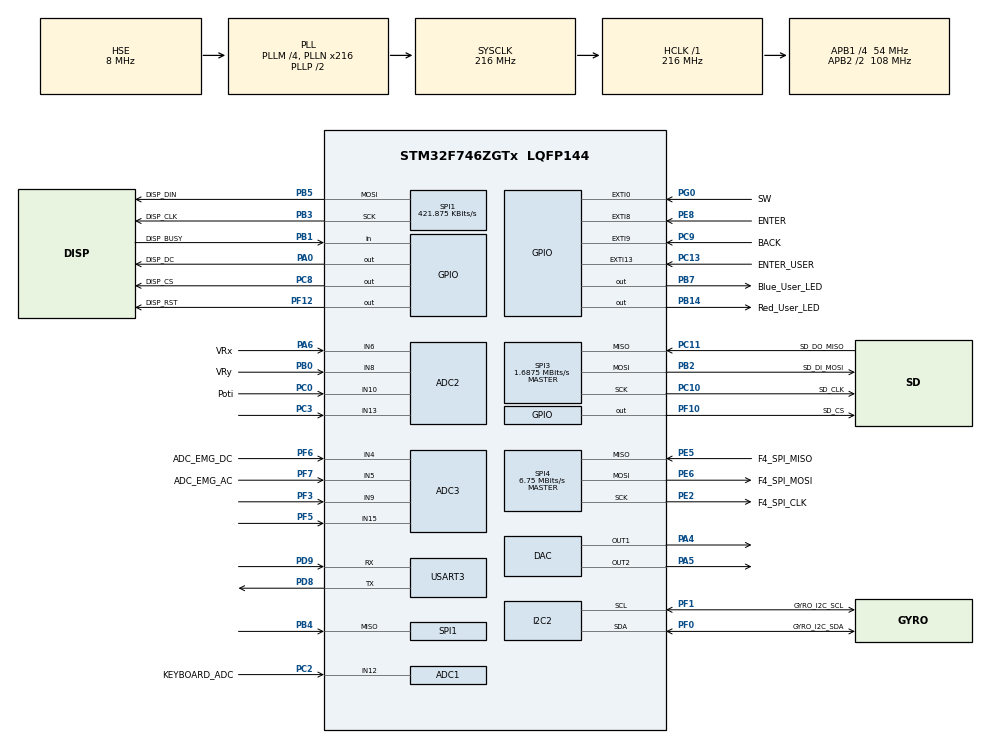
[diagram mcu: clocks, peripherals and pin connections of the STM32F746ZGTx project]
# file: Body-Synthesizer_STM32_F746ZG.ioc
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ADC1.Channel-0\#ChannelRegularConversion=ADC_CHANNEL_12
ADC1.ClockPrescaler=ADC_CLOCK_SYNC_PCLK_DIV8
ADC1.DMAContinuousRequests=ENABLE
ADC1.EOCSelection=ADC_EOC_SEQ_CONV
ADC1.ExternalTrigConv=ADC_EXTERNALTRIGCONV_T5_TRGO
ADC1.NbrOfConversion=1
ADC1.NbrOfConversionFlag=1
ADC1.Rank-0\#ChannelRegularConversion=1
ADC1.SamplingTime-0\#ChannelRegularConversion=ADC_SAMPLETIME_15CYCLES
ADC1.ScanConvMode=ADC_SCAN_ENABLE
ADC1.master=1
ADC2.Channel-0\#ChannelRegularConversion=ADC_CHANNEL_6
ADC2.Channel-1\#ChannelRegularConversion=ADC_CHANNEL_8
ADC2.Channel-2\#ChannelRegularConversion=ADC_CHANNEL_10
ADC2.Channel-3\#ChannelRegularConversion=ADC_CHANNEL_13
ADC2.ClockPrescaler=ADC_CLOCK_SYNC_PCLK_DIV8
ADC2.DMAContinuousRequests=ENABLE
ADC2.ExternalTrigConv=ADC_EXTERNALTRIGCONV_T6_TRGO
ADC2.NbrOfConversion=4
ADC2.NbrOfConversionFlag=1
ADC2.Rank-0\#ChannelRegularConversion=1
ADC2.Rank-1\#ChannelRegularConversion=2
ADC2.Rank-2\#ChannelRegularConversion=3
ADC2.Rank-3\#ChannelRegularConversion=4
ADC2.SamplingTime-0\#ChannelRegularConversion=ADC_SAMPLETIME_15CYCLES
ADC2.SamplingTime-1\#ChannelRegularConversion=ADC_SAMPLETIME_15CYCLES
ADC2.SamplingTime-2\#ChannelRegularConversion=ADC_SAMPLETIME_15CYCLES
ADC2.SamplingTime-3\#ChannelRegularConversion=ADC_SAMPLETIME_15CYCLES
ADC2.ScanConvMode=ADC_SCAN_ENABLE
ADC3.Channel-0\#ChannelRegularConversion=ADC_CHANNEL_4
ADC3.Channel-2\#ChannelRegularConversion=ADC_CHANNEL_5
ADC3.ClockPrescaler=ADC_CLOCK_SYNC_PCLK_DIV8
ADC3.DMAContinuousRequests=ENABLE
ADC3.EOCSelection=ADC_EOC_SEQ_CONV
ADC3.ExternalTrigConv=ADC_EXTERNALTRIGCONV_T1_TRGO
ADC3.NbrOfConversion=2
ADC3.NbrOfConversionFlag=1
ADC3.Rank-0\#ChannelRegularConversion=1
ADC3.Rank-2\#ChannelRegularConversion=2
ADC3.SamplingTime-0\#ChannelRegularConversion=ADC_SAMPLETIME_15CYCLES
ADC3.SamplingTime-2\#ChannelRegularConversion=ADC_SAMPLETIME_15CYCLES
ADC3.ScanConvMode=ADC_SCAN_ENABLE
DAC.DAC_Trigger=DAC_TRIGGER_T8_TRGO
DAC.DAC_Trigger2=DAC_TRIGGER_T8_TRGO
Dma.ADC1.2.Direction=DMA_PERIPH_TO_MEMORY
Dma.ADC1.2.FIFOMode=DMA_FIFOMODE_DISABLE
Dma.ADC1.2.Instance=DMA2_Stream0
Dma.ADC1.2.MemDataAlignment=DMA_MDATAALIGN_WORD
Dma.ADC1.2.MemInc=DMA_MINC_ENABLE
Dma.ADC1.2.Mode=DMA_NORMAL
Dma.ADC1.2.PeriphDataAlignment=DMA_PDATAALIGN_WORD
Dma.ADC1.2.PeriphInc=DMA_PINC_DISABLE
Dma.ADC1.2.Priority=DMA_PRIORITY_VERY_HIGH
Dma.ADC2.1.Direction=DMA_PERIPH_TO_MEMORY
Dma.ADC2.1.FIFOMode=DMA_FIFOMODE_DISABLE
Dma.ADC2.1.Instance=DMA2_Stream2
Dma.ADC2.1.MemDataAlignment=DMA_MDATAALIGN_HALFWORD
Dma.ADC2.1.MemInc=DMA_MINC_ENABLE
Dma.ADC2.1.Mode=DMA_CIRCULAR
Dma.ADC2.1.PeriphDataAlignment=DMA_PDATAALIGN_HALFWORD
Dma.ADC2.1.PeriphInc=DMA_PINC_DISABLE
Dma.ADC2.1.Priority=DMA_PRIORITY_HIGH
Dma.ADC3.3.Direction=DMA_PERIPH_TO_MEMORY
Dma.ADC3.3.FIFOMode=DMA_FIFOMODE_DISABLE
Dma.ADC3.3.Instance=DMA2_Stream1
Dma.ADC3.3.MemDataAlignment=DMA_MDATAALIGN_WORD
Dma.ADC3.3.MemInc=DMA_MINC_ENABLE
Dma.ADC3.3.Mode=DMA_CIRCULAR
Dma.ADC3.3.PeriphDataAlignment=DMA_PDATAALIGN_WORD
Dma.ADC3.3.PeriphInc=DMA_PINC_DISABLE
Dma.ADC3.3.Priority=DMA_PRIORITY_HIGH
Dma.DAC1.0.Direction=DMA_MEMORY_TO_PERIPH
Dma.DAC1.0.FIFOMode=DMA_FIFOMODE_DISABLE
Dma.DAC1.0.Instance=DMA1_Stream5
Dma.DAC1.0.MemDataAlignment=DMA_MDATAALIGN_WORD
Dma.DAC1.0.MemInc=DMA_MINC_ENABLE
Dma.DAC1.0.Mode=DMA_CIRCULAR
Dma.DAC1.0.PeriphDataAlignment=DMA_PDATAALIGN_WORD
Dma.DAC1.0.PeriphInc=DMA_PINC_DISABLE
Dma.DAC1.0.Priority=DMA_PRIORITY_VERY_HIGH
Dma.DAC2.4.Direction=DMA_MEMORY_TO_PERIPH
Dma.DAC2.4.FIFOMode=DMA_FIFOMODE_DISABLE
Dma.DAC2.4.Instance=DMA1_Stream6
Dma.DAC2.4.MemDataAlignment=DMA_MDATAALIGN_WORD
Dma.DAC2.4.MemInc=DMA_MINC_ENABLE
Dma.DAC2.4.Mode=DMA_CIRCULAR
Dma.DAC2.4.PeriphDataAlignment=DMA_PDATAALIGN_WORD
Dma.DAC2.4.PeriphInc=DMA_PINC_DISABLE
Dma.DAC2.4.Priority=DMA_PRIORITY_VERY_HIGH
Dma.Request0=DAC1
Dma.Request1=ADC2
Dma.Request2=ADC1
Dma.Request3=ADC3
Dma.Request4=DAC2
Dma.Request5=SPI4_RX
Dma.Request6=SPI4_TX
Dma.SPI4_RX.5.Direction=DMA_PERIPH_TO_MEMORY
Dma.SPI4_RX.5.FIFOMode=DMA_FIFOMODE_DISABLE
Dma.SPI4_RX.5.Instance=DMA2_Stream3
Dma.SPI4_RX.5.MemDataAlignment=DMA_MDATAALIGN_BYTE
Dma.SPI4_RX.5.MemInc=DMA_MINC_ENABLE
Dma.SPI4_RX.5.Mode=DMA_NORMAL
Dma.SPI4_RX.5.PeriphDataAlignment=DMA_PDATAALIGN_BYTE
Dma.SPI4_RX.5.PeriphInc=DMA_PINC_DISABLE
Dma.SPI4_RX.5.Priority=DMA_PRIORITY_LOW
Dma.SPI4_TX.6.Direction=DMA_MEMORY_TO_PERIPH
Dma.SPI4_TX.6.FIFOMode=DMA_FIFOMODE_DISABLE
Dma.SPI4_TX.6.Instance=DMA2_Stream4
Dma.SPI4_TX.6.MemDataAlignment=DMA_MDATAALIGN_BYTE
Dma.SPI4_TX.6.MemInc=DMA_MINC_ENABLE
Dma.SPI4_TX.6.Mode=DMA_NORMAL
Dma.SPI4_TX.6.PeriphDataAlignment=DMA_PDATAALIGN_BYTE
Dma.SPI4_TX.6.PeriphInc=DMA_PINC_DISABLE
Dma.SPI4_TX.6.Priority=DMA_PRIORITY_LOW
FATFS._MAX_SS=4096
FATFS._USE_LFN=1
I2C2.Timing=0x20404768
Mcu.Family=STM32F7
Mcu.Name=STM32F746ZGTx
Mcu.Package=LQFP144
NVIC.ADC_IRQn=true\:0\:0\:false\:false\:true\:true\:true
NVIC.DMA1_Stream5_IRQn=true\:0\:0\:false\:false\:true\:false\:true
NVIC.DMA1_Stream6_IRQn=true\:0\:0\:false\:false\:true\:false\:true
NVIC.DMA2_Stream0_IRQn=true\:1\:0\:true\:false\:true\:false\:true
NVIC.DMA2_Stream1_IRQn=true\:1\:0\:true\:false\:true\:false\:true
NVIC.DMA2_Stream2_IRQn=true\:2\:0\:true\:false\:true\:false\:true
NVIC.DMA2_Stream3_IRQn=true\:1\:0\:true\:false\:true\:false\:true
NVIC.DMA2_Stream4_IRQn=true\:1\:0\:true\:false\:true\:false\:true
NVIC.EXTI15_10_IRQn=true\:1\:0\:true\:false\:true\:true\:true
NVIC.EXTI9_5_IRQn=true\:0\:0\:true\:false\:true\:true\:true
NVIC.PriorityGroup=NVIC_PRIORITYGROUP_4
NVIC.SPI4_IRQn=true\:1\:0\:true\:false\:true\:true\:true
NVIC.TIM1_BRK_TIM9_IRQn=true\:1\:0\:true\:false\:true\:true\:true
NVIC.TIM2_IRQn=true\:1\:0\:true\:false\:true\:true\:true
NVIC.TIM3_IRQn=true\:0\:0\:true\:false\:true\:true\:true
NVIC.TIM4_IRQn=true\:1\:0\:true\:false\:true\:true\:true
NVIC.TIM5_IRQn=true\:1\:0\:true\:false\:true\:true\:true
NVIC.TIM7_IRQn=true\:1\:0\:true\:false\:true\:true\:true
NVIC.TIM8_TRG_COM_TIM14_IRQn=true\:1\:0\:true\:false\:true\:true\:true
PA0/WKUP.GPIO_Label=DISP_DC
PA0/WKUP.Signal=GPIO_Output
PA2.Signal=USART2_TX
PA4.Signal=COMP_DAC1_group
PA5.Signal=COMP_DAC2_group
PA6.GPIO_Label=VRx
PA6.Signal=ADCx_IN6
PB0.GPIO_Label=VRy
PB0.Signal=ADCx_IN8
PB1.GPIO_Label=DISP_BUSY
PB1.Signal=GPIO_Input
PB14.GPIO_Label=Red_User_LED
PB14.Signal=GPIO_Output
PB2.GPIO_Label=SD_DI_MOSI
PB2.Mode=Full_Duplex_Master
PB2.Signal=SPI3_MOSI
PB3.GPIO_Label=DISP_CLK
PB3.Mode=Full_Duplex_Master
PB3.Signal=SPI1_SCK
PB4.Mode=Full_Duplex_Master
PB4.Signal=SPI1_MISO
PB5.GPIO_Label=DISP_DIN
PB5.Mode=Full_Duplex_Master
PB5.Signal=SPI1_MOSI
PB7.GPIO_Label=Blue_User_LED
PB7.Signal=GPIO_Output
PC0.GPIO_Label=Poti
PC0.Signal=ADCx_IN10
PC10.GPIO_Label=SD_CLK
PC10.Mode=Full_Duplex_Master
PC10.Signal=SPI3_SCK
PC11.GPIO_Label=SD_DO_MISO
PC11.Mode=Full_Duplex_Master
PC11.Signal=SPI3_MISO
PC13.GPIO_Label=ENTER_USER
PC13.Signal=GPXTI13
PC2.GPIO_Label=KEYBOARD_ADC
PC2.Signal=ADCx_IN12
PC3.Signal=ADCx_IN13
PC8.GPIO_Label=DISP_CS
PC8.GPIO_ModeDefaultOutputPP=GPIO_MODE_OUTPUT_PP
PC8.Signal=GPIO_Output
PC9.GPIO_Label=BACK
PC9.Signal=GPXTI9
PD6.Signal=USART2_RX
PD8.Mode=Asynchronous
PD8.Signal=USART3_TX
PD9.Mode=Asynchronous
PD9.Signal=USART3_RX
PE2.GPIO_Label=F4_SPI_CLK
PE2.Mode=Full_Duplex_Master
PE2.Signal=SPI4_SCK
PE5.GPIO_Label=F4_SPI_MISO
PE5.Mode=Full_Duplex_Master
PE5.Signal=SPI4_MISO
PE6.GPIO_Label=F4_SPI_MOSI
PE6.Mode=Full_Duplex_Master
PE6.Signal=SPI4_MOSI
PE8.GPIO_Label=ENTER
PE8.Signal=GPXTI8
PF0.GPIO_Label=GYRO_I2C_SDA
PF0.Mode=I2C
PF0.Signal=I2C2_SDA
PF1.GPIO_Label=GYRO_I2C_SCL
PF1.Mode=I2C
PF1.Signal=I2C2_SCL
PF10.GPIO_Label=SD_CS
PF10.Signal=GPIO_Output
PF12.GPIO_Label=DISP_RST
PF12.Signal=GPIO_Output
PF3.Mode=IN9
PF3.Signal=ADC3_IN9
PF5.Mode=IN15
PF5.Signal=ADC3_IN15
PF6.GPIO_Label=ADC_EMG_DC
PF6.Mode=IN4
PF6.Signal=ADC3_IN4
PF7.GPIO_Label=ADC_EMG_AC
PF7.Mode=IN5
PF7.Signal=ADC3_IN5
PG0.GPIO_Label=SW
PG0.GPIO_ModeDefaultEXTI=GPIO_MODE_IT_FALLING
PG0.Signal=GPXTI0
PH0/OSC_IN.Mode=HSE-External-Oscillator
PH0/OSC_IN.Signal=RCC_OSC_IN
PH1/OSC_OUT.Mode=HSE-External-Oscillator
PH1/OSC_OUT.Signal=RCC_OSC_OUT
ProjectManager.HeapSize=0x200
ProjectManager.StackSize=0x400
ProjectManager.TargetToolchain=STM32CubeIDE
RCC.AHBFreq_Value=216000000
RCC.APB1CLKDivider=RCC_HCLK_DIV4
RCC.APB1Freq_Value=54000000
RCC.APB1TimFreq_Value=108000000
RCC.APB2CLKDivider=RCC_HCLK_DIV2
RCC.APB2Freq_Value=108000000
RCC.APB2TimFreq_Value=216000000
RCC.CortexFreq_Value=216000000
RCC.HCLKFreq_Value=216000000
RCC.HSE_VALUE=8000000
RCC.HSI_VALUE=16000000
RCC.LSE_VALUE=32768
RCC.PLLM=4
RCC.PLLN=216
RCC.PLLSourceVirtual=RCC_PLLSOURCE_HSE
RCC.SYSCLKFreq_VALUE=216000000
RCC.SYSCLKSource=RCC_SYSCLKSOURCE_PLLCLK
RCC.USBFreq_Value=216000000
RCC.VCOOutputFreq_Value=432000000
SH.ADCx_IN10.0=ADC2_IN10,IN10
SH.ADCx_IN12.0=ADC1_IN12,IN12
SH.ADCx_IN13.0=ADC2_IN13,IN13
SH.ADCx_IN6.0=ADC2_IN6,IN6
SH.ADCx_IN8.0=ADC2_IN8,IN8
SH.COMP_DAC1_group.0=DAC_OUT1,DAC_OUT1
SH.COMP_DAC2_group.0=DAC_OUT2,DAC_OUT2
SPI1.BaudRatePrescaler=SPI_BAUDRATEPRESCALER_256
SPI1.CalculateBaudRate=421.875 KBits/s
SPI1.DataSize=SPI_DATASIZE_8BIT
SPI1.Direction=SPI_DIRECTION_2LINES
SPI1.Mode=SPI_MODE_MASTER
SPI1.VirtualType=VM_MASTER
SPI3.BaudRatePrescaler=SPI_BAUDRATEPRESCALER_32
SPI3.CalculateBaudRate=1.6875 MBits/s
SPI3.DataSize=SPI_DATASIZE_8BIT
SPI3.Direction=SPI_DIRECTION_2LINES
SPI3.Mode=SPI_MODE_MASTER
SPI3.VirtualType=VM_MASTER
SPI4.BaudRatePrescaler=SPI_BAUDRATEPRESCALER_16
SPI4.CLKPolarity=SPI_POLARITY_HIGH
SPI4.CalculateBaudRate=6.75 MBits/s
SPI4.DataSize=SPI_DATASIZE_8BIT
SPI4.Direction=SPI_DIRECTION_2LINES
SPI4.Mode=SPI_MODE_MASTER
SPI4.NSSPMode=SPI_NSS_PULSE_DISABLE
SPI4.VirtualType=VM_MASTER
TIM1.AutoReloadPreload=TIM_AUTORELOAD_PRELOAD_ENABLE
TIM1.Period=10000
TIM1.Prescaler=215
TIM1.TIM_MasterOutputTrigger=TIM_TRGO_UPDATE
TIM2.Period=59999
TIM2.Prescaler=4
TIM3.AutoReloadPreload=TIM_AUTORELOAD_PRELOAD_ENABLE
TIM3.TIM_MasterOutputTrigger=TIM_TRGO_UPDATE
TIM4.Period=59999
TIM4.Prescaler=4
TIM5.AutoReloadPreload=TIM_AUTORELOAD_PRELOAD_ENABLE
TIM5.Period=53999
TIM5.TIM_MasterOutputTrigger=TIM_TRGO_UPDATE
TIM6.AutoReloadPreload=TIM_AUTORELOAD_PRELOAD_ENABLE
TIM6.Period=53999
TIM6.TIM_MasterOutputTrigger=TIM_TRGO_UPDATE
TIM7.AutoReloadPreload=TIM_AUTORELOAD_PRELOAD_ENABLE
TIM7.TIM_MasterOutputTrigger=TIM_TRGO_RESET
TIM8.AutoReloadPreload=TIM_AUTORELOAD_PRELOAD_ENABLE
TIM8.Channel-PWM\ Generation4\ No\ Output=TIM_CHANNEL_4
TIM8.Period=10800
TIM8.Prescaler=0
TIM8.RepetitionCounter=0
TIM8.TIM_MasterOutputTrigger=TIM_TRGO_UPDATE
USART3.VirtualMode-Asynchronous=VM_ASYNC
VP_FATFS_VS_Generic.Mode=User_defined
VP_TIM1_VS_ClockSourceINT.Mode=Internal
VP_TIM2_VS_ClockSourceINT.Mode=Internal
VP_TIM3_VS_ClockSourceINT.Mode=Internal
VP_TIM4_VS_ClockSourceINT.Mode=Internal
VP_TIM5_VS_ClockSourceINT.Mode=Internal
VP_TIM6_VS_ClockSourceINT.Mode=Enable_Timer
VP_TIM7_VS_ClockSourceINT.Mode=Enable_Timer
VP_TIM8_VS_ClockSourceINT.Mode=Internal
VP_TIM8_VS_no_output4.Mode=PWM Generation4 No Output
board=custom

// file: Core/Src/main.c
/* USER CODE BEGIN Header */
/**
 ******************************************************************************
 * @file           : main.c
 * @brief          : Main program body
 ******************************************************************************
 * @attention
 *
 * <h2><center>&copy; Copyright (c) 2020 STMicroelectronics.
 * All rights reserved.</center></h2>
 *
 * This software component is licensed by ST under BSD 3-Clause license,
 * the "License"; You may not use this file except in compliance with the
 * License. You may obtain a copy of the License at:
 *                        opensource.org/licenses/BSD-3-Clause
 *
 ******************************************************************************
 */
/* USER CODE END Header */
#include "main.h"
#include "fatfs.h"

/* USER CODE BEGIN Includes */

//For SD card
#include <stdlib.h>
#include <stdio.h>
#include <string.h>
#include <stdbool.h>
#include "fatfs_sd.h"
#include "sd_card.h"
/* USER CODE END Includes */

ADC_HandleTypeDef hadc1;
ADC_HandleTypeDef hadc2;
ADC_HandleTypeDef hadc3;
DMA_HandleTypeDef hdma_adc1;
DMA_HandleTypeDef hdma_adc2;
DMA_HandleTypeDef hdma_adc3;

DAC_HandleTypeDef hdac;
DMA_HandleTypeDef hdma_dac1;
DMA_HandleTypeDef hdma_dac2;

I2C_HandleTypeDef hi2c2;

SPI_HandleTypeDef hspi1;
SPI_HandleTypeDef hspi3;
SPI_HandleTypeDef hspi4;
DMA_HandleTypeDef hdma_spi4_rx;
DMA_HandleTypeDef hdma_spi4_tx;

TIM_HandleTypeDef htim1;
TIM_HandleTypeDef htim2;
TIM_HandleTypeDef htim3;
TIM_HandleTypeDef htim4;
TIM_HandleTypeDef htim5;
TIM_HandleTypeDef htim6;
TIM_HandleTypeDef htim7;
TIM_HandleTypeDef htim8;

UART_HandleTypeDef huart3;

void SystemClock_Config(void);
static void MX_GPIO_Init(void);
static void MX_TIM8_Init(void);
static void MX_DMA_Init(void);
static void MX_DAC_Init(void);
static void MX_TIM6_Init(void);
static void MX_USART3_UART_Init(void);
static void MX_ADC2_Init(void);
static void MX_SPI1_Init(void);
static void MX_SPI3_Init(void);
static void MX_TIM2_Init(void);
static void MX_TIM4_Init(void);
static void MX_TIM1_Init(void);
static void MX_ADC1_Init(void);
static void MX_TIM5_Init(void);
static void MX_ADC3_Init(void);
static void MX_I2C2_Init(void);
static void MX_SPI4_Init(void);
static void MX_TIM7_Init(void);
static void MX_TIM3_Init(void);

/* USER CODE BEGIN 0 */

void HAL_ADC_ConvHalfCpltCallback(ADC_HandleTypeDef* hadc) {

	inputBuffer_position = HALF_BLOCK;
	if(hadc->Instance == ADC3){

		emg_peak_detection();
		ecg_heartrate();
	}
}
void HAL_ADC_ConvCpltCallback(ADC_HandleTypeDef* hadc) {

	inputBuffer_position = FULL_BLOCK;
	if(hadc->Instance == ADC3){

		emg_peak_detection();
		ecg_heartrate();
	}
}

/* DAC CHANNEL FUNCTIONS begin*********************/
bool Init_complete = false;

// DAC_CHANNEL_2
void HAL_DACEx_ConvHalfCpltCallbackCh2(DAC_HandleTypeDef* hdac) {

	outputBuffer_position = HALF_BLOCK;

	if (Init_complete){
		Signal_Synthesis(&signals1, 1);
	}
	else
		Init_complete = initRamp();
}

void HAL_DACEx_ConvCpltCallbackCh2(DAC_HandleTypeDef* hdac) {

	outputBuffer_position = FULL_BLOCK;

	if (Init_complete){
		Signal_Synthesis(&signals1, 1);
	}
	else
		Init_complete = initRamp();
}
/* DAC CHANNEL FUNCTIONS end*********************/

/* USER CODE END 0 */

int main(void)
{

  /* MCU Configuration--------------------------------------------------------*/

  /* Reset of all peripherals, Initializes the Flash interface and the Systick. */
  HAL_Init();

  /* Configure the system clock */
  SystemClock_Config();

  /* USER CODE BEGIN SysInit */

	MX_DMA_Init();

  /* USER CODE END SysInit */

  /* Initialize all configured peripherals */
  MX_GPIO_Init();
  MX_TIM8_Init();
  MX_DMA_Init();
  MX_DAC_Init();
  MX_TIM6_Init();
  MX_USART3_UART_Init();
  MX_ADC2_Init();
  MX_SPI1_Init();
  MX_SPI3_Init();
  MX_TIM2_Init();
  MX_TIM4_Init();
  MX_FATFS_Init();
  MX_TIM1_Init();
  MX_ADC1_Init();
  MX_TIM5_Init();
  MX_ADC3_Init();
  MX_I2C2_Init();
  MX_SPI4_Init();
  MX_TIM7_Init();
  MX_TIM3_Init();
  /* USER CODE BEGIN 2 */

	printf("***Bodysynthesizer Paul*** \r\n");

	/* INIT FUNCTIONS begin*********************/

	printf("Begin Init\r\n");
	if(Signal_Synthesis_Init(htim8, hdac) != HAL_OK) {
		printf("Signal Synthesis init failed\n");
	}

	effects_init();

	if(Filters_Init() == FILTER_FAIL) {
		printf("Filters init failed\n");
	}

	if(Tremolo_Init(&Tremolo) == TREMOLO_FAIL) {
		printf("Tremolo init failed\n");
	}

	if(Distortion_Init() == DISTORTION_FAIL) {
		printf("Distortion init failed\n");
	}

	if(ADSR_Init() == ADSR_FAIL) {
		printf("ADSR init failed\n");
	}

	keyboard_init(&hadc1, &htim5);

	//Drummachine
	Drum_Computer_Init();

	//Gyros SPI
	spiC_Init(&hspi4, &htim7);

	//EMG init
	emg_init(&hadc3,&htim1);
	ecg_init();

	// WahWah Init
	WahWah_Init(&WahWah);

	// Interface Init
	II_init();

	// Display Init (should be done after the rest is initialized)
	if(Display_Init(&Display) == DISPLAY_FAIL)
		printf("Display init failed\n");

	printf("End Init\r\n");
	/* INIT FUNCTIONS end*********************/

	/* START FUNCTIONS begin *****************/
	printf("Begin Start Functions\r\n");

	// Start Display
	frame_buffer = (unsigned char*)malloc(EPD_WIDTH * EPD_HEIGHT / 8);
	Display_Start(&epd, &paint, frame_buffer);	// https://github.com/soonuse/epd-library-stm32

	// Start DAC-DMA
	printf("start DAC\r\n");
	//		HAL_DAC_Start_DMA(&hdac, DAC_CHANNEL_1, (uint32_t*)calculate_vector1 ,BLOCKSIZE, DAC_ALIGN_12B_R);
	HAL_DAC_Start_DMA(&hdac, DAC_CHANNEL_2, (uint32_t*)calculate_vector1 ,BLOCKSIZE, DAC_ALIGN_12B_R);

	// Start Timer and ADC-DMA for the keyboard (ADC1)
	keyboard_start_read();

	// Start Timer and ADC-DMA for the joystick and the potentiometer (ADC2)
	SetTimerSettings(&htim6, 500);	// Timer 6 default: 2000 Hz
	printf("start Button ADC\r\n");
	HAL_TIM_Base_Start(&htim6);
	HAL_ADC_Start_DMA(&hadc2, (uint32_t*)Display.ADC2inputs, 4);

	// Start Timer and ADC-DMA for the EMG-sensor (ADC3)
	emg_start_read();

	//Start Interface
	II_startInterface(&htim3);

	printf("End Start Functions\r\n");
	/* START FUNCTIONS end *****************/

  /* USER CODE END 2 */

  /* Infinite loop */
	while(1) {

    /* USER CODE BEGIN 3 */

		/* USER CODE END WHILE */
	}

	return 0;
  /* USER CODE END 3 */
}

void SystemClock_Config(void)
{
  RCC_OscInitTypeDef RCC_OscInitStruct = {0};
  RCC_ClkInitTypeDef RCC_ClkInitStruct = {0};
  RCC_PeriphCLKInitTypeDef PeriphClkInitStruct = {0};

  /** Configure the main internal regulator output voltage
  */
  __HAL_RCC_PWR_CLK_ENABLE();
  __HAL_PWR_VOLTAGESCALING_CONFIG(PWR_REGULATOR_VOLTAGE_SCALE1);
  /** Initializes the RCC Oscillators according to the specified parameters
  * in the RCC_OscInitTypeDef structure.
  */
  RCC_OscInitStruct.OscillatorType = RCC_OSCILLATORTYPE_HSE;
  RCC_OscInitStruct.HSEState = RCC_HSE_ON;
  RCC_OscInitStruct.PLL.PLLState = RCC_PLL_ON;
  RCC_OscInitStruct.PLL.PLLSource = RCC_PLLSOURCE_HSE;
  RCC_OscInitStruct.PLL.PLLM = 4;
  RCC_OscInitStruct.PLL.PLLN = 216;
  RCC_OscInitStruct.PLL.PLLP = RCC_PLLP_DIV2;
  RCC_OscInitStruct.PLL.PLLQ = 2;
  if (HAL_RCC_OscConfig(&RCC_OscInitStruct) != HAL_OK)
  {
    Error_Handler();
  }
  /** Activate the Over-Drive mode
  */
  if (HAL_PWREx_EnableOverDrive() != HAL_OK)
  {
    Error_Handler();
  }
  /** Initializes the CPU, AHB and APB buses clocks
  */
  RCC_ClkInitStruct.ClockType = RCC_CLOCKTYPE_HCLK|RCC_CLOCKTYPE_SYSCLK
                              |RCC_CLOCKTYPE_PCLK1|RCC_CLOCKTYPE_PCLK2;
  RCC_ClkInitStruct.SYSCLKSource = RCC_SYSCLKSOURCE_PLLCLK;
  RCC_ClkInitStruct.AHBCLKDivider = RCC_SYSCLK_DIV1;
  RCC_ClkInitStruct.APB1CLKDivider = RCC_HCLK_DIV4;
  RCC_ClkInitStruct.APB2CLKDivider = RCC_HCLK_DIV2;

  if (HAL_RCC_ClockConfig(&RCC_ClkInitStruct, FLASH_LATENCY_7) != HAL_OK)
  {
    Error_Handler();
  }
  PeriphClkInitStruct.PeriphClockSelection = RCC_PERIPHCLK_USART3|RCC_PERIPHCLK_I2C2;
  PeriphClkInitStruct.Usart3ClockSelection = RCC_USART3CLKSOURCE_PCLK1;
  PeriphClkInitStruct.I2c2ClockSelection = RCC_I2C2CLKSOURCE_PCLK1;
  if (HAL_RCCEx_PeriphCLKConfig(&PeriphClkInitStruct) != HAL_OK)
  {
    Error_Handler();
  }
}

static void MX_ADC1_Init(void)
{

  ADC_ChannelConfTypeDef sConfig = {0};

  /** Configure the global features of the ADC (Clock, Resolution, Data Alignment and number of conversion)
  */
  hadc1.Instance = ADC1;
  hadc1.Init.ClockPrescaler = ADC_CLOCK_SYNC_PCLK_DIV8;
  hadc1.Init.Resolution = ADC_RESOLUTION_12B;
  hadc1.Init.ScanConvMode = ADC_SCAN_ENABLE;
  hadc1.Init.ContinuousConvMode = DISABLE;
  hadc1.Init.DiscontinuousConvMode = DISABLE;
  hadc1.Init.ExternalTrigConvEdge = ADC_EXTERNALTRIGCONVEDGE_RISING;
  hadc1.Init.ExternalTrigConv = ADC_EXTERNALTRIGCONV_T5_TRGO;
  hadc1.Init.DataAlign = ADC_DATAALIGN_RIGHT;
  hadc1.Init.NbrOfConversion = 1;
  hadc1.Init.DMAContinuousRequests = ENABLE;
  hadc1.Init.EOCSelection = ADC_EOC_SEQ_CONV;
  if (HAL_ADC_Init(&hadc1) != HAL_OK)
  {
    Error_Handler();
  }
  /** Configure for the selected ADC regular channel its corresponding rank in the sequencer and its sample time.
  */
  sConfig.Channel = ADC_CHANNEL_12;
  sConfig.Rank = ADC_REGULAR_RANK_1;
  sConfig.SamplingTime = ADC_SAMPLETIME_15CYCLES;
  if (HAL_ADC_ConfigChannel(&hadc1, &sConfig) != HAL_OK)
  {
    Error_Handler();
  }

}

static void MX_ADC2_Init(void)
{

  ADC_ChannelConfTypeDef sConfig = {0};

  /** Configure the global features of the ADC (Clock, Resolution, Data Alignment and number of conversion)
  */
  hadc2.Instance = ADC2;
  hadc2.Init.ClockPrescaler = ADC_CLOCK_SYNC_PCLK_DIV8;
  hadc2.Init.Resolution = ADC_RESOLUTION_12B;
  hadc2.Init.ScanConvMode = ADC_SCAN_ENABLE;
  hadc2.Init.ContinuousConvMode = DISABLE;
  hadc2.Init.DiscontinuousConvMode = DISABLE;
  hadc2.Init.ExternalTrigConvEdge = ADC_EXTERNALTRIGCONVEDGE_RISING;
  hadc2.Init.ExternalTrigConv = ADC_EXTERNALTRIGCONV_T6_TRGO;
  hadc2.Init.DataAlign = ADC_DATAALIGN_RIGHT;
  hadc2.Init.NbrOfConversion = 4;
  hadc2.Init.DMAContinuousRequests = ENABLE;
  hadc2.Init.EOCSelection = ADC_EOC_SINGLE_CONV;
  if (HAL_ADC_Init(&hadc2) != HAL_OK)
  {
    Error_Handler();
  }
  /** Configure for the selected ADC regular channel its corresponding rank in the sequencer and its sample time.
  */
  sConfig.Channel = ADC_CHANNEL_6;
  sConfig.Rank = ADC_REGULAR_RANK_1;
  sConfig.SamplingTime = ADC_SAMPLETIME_15CYCLES;
  if (HAL_ADC_ConfigChannel(&hadc2, &sConfig) != HAL_OK)
  {
    Error_Handler();
  }
  /** Configure for the selected ADC regular channel its corresponding rank in the sequencer and its sample time.
  */
  sConfig.Channel = ADC_CHANNEL_8;
  sConfig.Rank = ADC_REGULAR_RANK_2;
  if (HAL_ADC_ConfigChannel(&hadc2, &sConfig) != HAL_OK)
  {
    Error_Handler();
  }
  /** Configure for the selected ADC regular channel its corresponding rank in the sequencer and its sample time.
  */
  sConfig.Channel = ADC_CHANNEL_10;
  sConfig.Rank = ADC_REGULAR_RANK_3;
  if (HAL_ADC_ConfigChannel(&hadc2, &sConfig) != HAL_OK)
  {
    Error_Handler();
  }
  /** Configure for the selected ADC regular channel its corresponding rank in the sequencer and its sample time.
  */
  sConfig.Channel = ADC_CHANNEL_13;
  sConfig.Rank = ADC_REGULAR_RANK_4;
  if (HAL_ADC_ConfigChannel(&hadc2, &sConfig) != HAL_OK)
  {
    Error_Handler();
  }

}

static void MX_ADC3_Init(void)
{

  ADC_ChannelConfTypeDef sConfig = {0};

  /** Configure the global features of the ADC (Clock, Resolution, Data Alignment and number of conversion)
  */
  hadc3.Instance = ADC3;
  hadc3.Init.ClockPrescaler = ADC_CLOCK_SYNC_PCLK_DIV8;
  hadc3.Init.Resolution = ADC_RESOLUTION_12B;
  hadc3.Init.ScanConvMode = ADC_SCAN_ENABLE;
  hadc3.Init.ContinuousConvMode = DISABLE;
  hadc3.Init.DiscontinuousConvMode = DISABLE;
  hadc3.Init.ExternalTrigConvEdge = ADC_EXTERNALTRIGCONVEDGE_RISING;
  hadc3.Init.ExternalTrigConv = ADC_EXTERNALTRIGCONV_T1_TRGO;
  hadc3.Init.DataAlign = ADC_DATAALIGN_RIGHT;
  hadc3.Init.NbrOfConversion = 2;
  hadc3.Init.DMAContinuousRequests = ENABLE;
  hadc3.Init.EOCSelection = ADC_EOC_SEQ_CONV;
  if (HAL_ADC_Init(&hadc3) != HAL_OK)
  {
    Error_Handler();
  }
  /** Configure for the selected ADC regular channel its corresponding rank in the sequencer and its sample time.
  */
  sConfig.Channel = ADC_CHANNEL_4;
  sConfig.Rank = ADC_REGULAR_RANK_1;
  sConfig.SamplingTime = ADC_SAMPLETIME_15CYCLES;
  if (HAL_ADC_ConfigChannel(&hadc3, &sConfig) != HAL_OK)
  {
    Error_Handler();
  }
  /** Configure for the selected ADC regular channel its corresponding rank in the sequencer and its sample time.
  */
  sConfig.Channel = ADC_CHANNEL_5;
  sConfig.Rank = ADC_REGULAR_RANK_2;
  if (HAL_ADC_ConfigChannel(&hadc3, &sConfig) != HAL_OK)
  {
    Error_Handler();
  }

}

static void MX_DAC_Init(void)
{

  DAC_ChannelConfTypeDef sConfig = {0};

  /** DAC Initialization
  */
  hdac.Instance = DAC;
  if (HAL_DAC_Init(&hdac) != HAL_OK)
  {
    Error_Handler();
  }
  /** DAC channel OUT1 config
  */
  sConfig.DAC_Trigger = DAC_TRIGGER_T8_TRGO;
  sConfig.DAC_OutputBuffer = DAC_OUTPUTBUFFER_ENABLE;
  if (HAL_DAC_ConfigChannel(&hdac, &sConfig, DAC_CHANNEL_1) != HAL_OK)
  {
    Error_Handler();
  }
  /** DAC channel OUT2 config
  */
  if (HAL_DAC_ConfigChannel(&hdac, &sConfig, DAC_CHANNEL_2) != HAL_OK)
  {
    Error_Handler();
  }

}

static void MX_I2C2_Init(void)
{

  hi2c2.Instance = I2C2;
  hi2c2.Init.Timing = 0x20404768;
  hi2c2.Init.OwnAddress1 = 0;
  hi2c2.Init.AddressingMode = I2C_ADDRESSINGMODE_7BIT;
  hi2c2.Init.DualAddressMode = I2C_DUALADDRESS_DISABLE;
  hi2c2.Init.OwnAddress2 = 0;
  hi2c2.Init.OwnAddress2Masks = I2C_OA2_NOMASK;
  hi2c2.Init.GeneralCallMode = I2C_GENERALCALL_DISABLE;
  hi2c2.Init.NoStretchMode = I2C_NOSTRETCH_DISABLE;
  if (HAL_I2C_Init(&hi2c2) != HAL_OK)
  {
    Error_Handler();
  }
  /** Configure Analogue filter
  */
  if (HAL_I2CEx_ConfigAnalogFilter(&hi2c2, I2C_ANALOGFILTER_ENABLE) != HAL_OK)
  {
    Error_Handler();
  }
  /** Configure Digital filter
  */
  if (HAL_I2CEx_ConfigDigitalFilter(&hi2c2, 0) != HAL_OK)
  {
    Error_Handler();
  }

}

static void MX_SPI1_Init(void)
{

  /* SPI1 parameter configuration*/
  hspi1.Instance = SPI1;
  hspi1.Init.Mode = SPI_MODE_MASTER;
  hspi1.Init.Direction = SPI_DIRECTION_2LINES;
  hspi1.Init.DataSize = SPI_DATASIZE_8BIT;
  hspi1.Init.CLKPolarity = SPI_POLARITY_LOW;
  hspi1.Init.CLKPhase = SPI_PHASE_1EDGE;
  hspi1.Init.NSS = SPI_NSS_SOFT;
  hspi1.Init.BaudRatePrescaler = SPI_BAUDRATEPRESCALER_256;
  hspi1.Init.FirstBit = SPI_FIRSTBIT_MSB;
  hspi1.Init.TIMode = SPI_TIMODE_DISABLE;
  hspi1.Init.CRCCalculation = SPI_CRCCALCULATION_DISABLE;
  hspi1.Init.CRCPolynomial = 7;
  hspi1.Init.CRCLength = SPI_CRC_LENGTH_DATASIZE;
  hspi1.Init.NSSPMode = SPI_NSS_PULSE_ENABLE;
  if (HAL_SPI_Init(&hspi1) != HAL_OK)
  {
    Error_Handler();
  }

}

static void MX_SPI3_Init(void)
{

  /* SPI3 parameter configuration*/
  hspi3.Instance = SPI3;
  hspi3.Init.Mode = SPI_MODE_MASTER;
  hspi3.Init.Direction = SPI_DIRECTION_2LINES;
  hspi3.Init.DataSize = SPI_DATASIZE_8BIT;
  hspi3.Init.CLKPolarity = SPI_POLARITY_LOW;
  hspi3.Init.CLKPhase = SPI_PHASE_1EDGE;
  hspi3.Init.NSS = SPI_NSS_SOFT;
  hspi3.Init.BaudRatePrescaler = SPI_BAUDRATEPRESCALER_32;
  hspi3.Init.FirstBit = SPI_FIRSTBIT_MSB;
  hspi3.Init.TIMode = SPI_TIMODE_DISABLE;
  hspi3.Init.CRCCalculation = SPI_CRCCALCULATION_DISABLE;
  hspi3.Init.CRCPolynomial = 7;
  hspi3.Init.CRCLength = SPI_CRC_LENGTH_DATASIZE;
  hspi3.Init.NSSPMode = SPI_NSS_PULSE_ENABLE;
  if (HAL_SPI_Init(&hspi3) != HAL_OK)
  {
    Error_Handler();
  }

}

static void MX_SPI4_Init(void)
{

  /* SPI4 parameter configuration*/
  hspi4.Instance = SPI4;
  hspi4.Init.Mode = SPI_MODE_MASTER;
  hspi4.Init.Direction = SPI_DIRECTION_2LINES;
  hspi4.Init.DataSize = SPI_DATASIZE_8BIT;
  hspi4.Init.CLKPolarity = SPI_POLARITY_HIGH;
  hspi4.Init.CLKPhase = SPI_PHASE_1EDGE;
  hspi4.Init.NSS = SPI_NSS_SOFT;
  hspi4.Init.BaudRatePrescaler = SPI_BAUDRATEPRESCALER_16;
  hspi4.Init.FirstBit = SPI_FIRSTBIT_MSB;
  hspi4.Init.TIMode = SPI_TIMODE_DISABLE;
  hspi4.Init.CRCCalculation = SPI_CRCCALCULATION_DISABLE;
  hspi4.Init.CRCPolynomial = 7;
  hspi4.Init.CRCLength = SPI_CRC_LENGTH_DATASIZE;
  hspi4.Init.NSSPMode = SPI_NSS_PULSE_DISABLE;
  if (HAL_SPI_Init(&hspi4) != HAL_OK)
  {
    Error_Handler();
  }

}

static void MX_TIM1_Init(void)
{

  TIM_ClockConfigTypeDef sClockSourceConfig = {0};
  TIM_MasterConfigTypeDef sMasterConfig = {0};

  htim1.Instance = TIM1;
  htim1.Init.Prescaler = 215;
  htim1.Init.CounterMode = TIM_COUNTERMODE_UP;
  htim1.Init.Period = 10000;
  htim1.Init.ClockDivision = TIM_CLOCKDIVISION_DIV1;
  htim1.Init.RepetitionCounter = 0;
  htim1.Init.AutoReloadPreload = TIM_AUTORELOAD_PRELOAD_ENABLE;
  if (HAL_TIM_Base_Init(&htim1) != HAL_OK)
  {
    Error_Handler();
  }
  sClockSourceConfig.ClockSource = TIM_CLOCKSOURCE_INTERNAL;
  if (HAL_TIM_ConfigClockSource(&htim1, &sClockSourceConfig) != HAL_OK)
  {
    Error_Handler();
  }
  sMasterConfig.MasterOutputTrigger = TIM_TRGO_UPDATE;
  sMasterConfig.MasterOutputTrigger2 = TIM_TRGO2_RESET;
  sMasterConfig.MasterSlaveMode = TIM_MASTERSLAVEMODE_DISABLE;
  if (HAL_TIMEx_MasterConfigSynchronization(&htim1, &sMasterConfig) != HAL_OK)
  {
    Error_Handler();
  }

}

static void MX_TIM2_Init(void)
{

  TIM_ClockConfigTypeDef sClockSourceConfig = {0};
  TIM_MasterConfigTypeDef sMasterConfig = {0};

  htim2.Instance = TIM2;
  htim2.Init.Prescaler = 4;
  htim2.Init.CounterMode = TIM_COUNTERMODE_UP;
  htim2.Init.Period = 59999;
  htim2.Init.ClockDivision = TIM_CLOCKDIVISION_DIV1;
  htim2.Init.AutoReloadPreload = TIM_AUTORELOAD_PRELOAD_DISABLE;
  if (HAL_TIM_Base_Init(&htim2) != HAL_OK)
  {
    Error_Handler();
  }
  sClockSourceConfig.ClockSource = TIM_CLOCKSOURCE_INTERNAL;
  if (HAL_TIM_ConfigClockSource(&htim2, &sClockSourceConfig) != HAL_OK)
  {
    Error_Handler();
  }
  sMasterConfig.MasterOutputTrigger = TIM_TRGO_RESET;
  sMasterConfig.MasterSlaveMode = TIM_MASTERSLAVEMODE_DISABLE;
  if (HAL_TIMEx_MasterConfigSynchronization(&htim2, &sMasterConfig) != HAL_OK)
  {
    Error_Handler();
  }

}

static void MX_TIM3_Init(void)
{

  TIM_ClockConfigTypeDef sClockSourceConfig = {0};
  TIM_MasterConfigTypeDef sMasterConfig = {0};

  htim3.Instance = TIM3;
  htim3.Init.Prescaler = 0;
  htim3.Init.CounterMode = TIM_COUNTERMODE_UP;
  htim3.Init.Period = 65535;
  htim3.Init.ClockDivision = TIM_CLOCKDIVISION_DIV1;
  htim3.Init.AutoReloadPreload = TIM_AUTORELOAD_PRELOAD_ENABLE;
  if (HAL_TIM_Base_Init(&htim3) != HAL_OK)
  {
    Error_Handler();
  }
  sClockSourceConfig.ClockSource = TIM_CLOCKSOURCE_INTERNAL;
  if (HAL_TIM_ConfigClockSource(&htim3, &sClockSourceConfig) != HAL_OK)
  {
    Error_Handler();
  }
  sMasterConfig.MasterOutputTrigger = TIM_TRGO_UPDATE;
  sMasterConfig.MasterSlaveMode = TIM_MASTERSLAVEMODE_DISABLE;
  if (HAL_TIMEx_MasterConfigSynchronization(&htim3, &sMasterConfig) != HAL_OK)
  {
    Error_Handler();
  }

}

static void MX_TIM4_Init(void)
{

  TIM_ClockConfigTypeDef sClockSourceConfig = {0};
  TIM_MasterConfigTypeDef sMasterConfig = {0};

  htim4.Instance = TIM4;
  htim4.Init.Prescaler = 4;
  htim4.Init.CounterMode = TIM_COUNTERMODE_UP;
  htim4.Init.Period = 59999;
  htim4.Init.ClockDivision = TIM_CLOCKDIVISION_DIV1;
  htim4.Init.AutoReloadPreload = TIM_AUTORELOAD_PRELOAD_DISABLE;
  if (HAL_TIM_Base_Init(&htim4) != HAL_OK)
  {
    Error_Handler();
  }
  sClockSourceConfig.ClockSource = TIM_CLOCKSOURCE_INTERNAL;
  if (HAL_TIM_ConfigClockSource(&htim4, &sClockSourceConfig) != HAL_OK)
  {
    Error_Handler();
  }
  sMasterConfig.MasterOutputTrigger = TIM_TRGO_RESET;
  sMasterConfig.MasterSlaveMode = TIM_MASTERSLAVEMODE_DISABLE;
  if (HAL_TIMEx_MasterConfigSynchronization(&htim4, &sMasterConfig) != HAL_OK)
  {
    Error_Handler();
  }

}

static void MX_TIM5_Init(void)
{

  TIM_ClockConfigTypeDef sClockSourceConfig = {0};
  TIM_MasterConfigTypeDef sMasterConfig = {0};

  htim5.Instance = TIM5;
  htim5.Init.Prescaler = 0;
  htim5.Init.CounterMode = TIM_COUNTERMODE_UP;
  htim5.Init.Period = 53999;
  htim5.Init.ClockDivision = TIM_CLOCKDIVISION_DIV1;
  htim5.Init.AutoReloadPreload = TIM_AUTORELOAD_PRELOAD_ENABLE;
  if (HAL_TIM_Base_Init(&htim5) != HAL_OK)
  {
    Error_Handler();
  }
  sClockSourceConfig.ClockSource = TIM_CLOCKSOURCE_INTERNAL;
  if (HAL_TIM_ConfigClockSource(&htim5, &sClockSourceConfig) != HAL_OK)
  {
    Error_Handler();
  }
  sMasterConfig.MasterOutputTrigger = TIM_TRGO_UPDATE;
  sMasterConfig.MasterSlaveMode = TIM_MASTERSLAVEMODE_DISABLE;
  if (HAL_TIMEx_MasterConfigSynchronization(&htim5, &sMasterConfig) != HAL_OK)
  {
    Error_Handler();
  }

}

static void MX_TIM6_Init(void)
{

  TIM_MasterConfigTypeDef sMasterConfig = {0};

  htim6.Instance = TIM6;
  htim6.Init.Prescaler = 0;
  htim6.Init.CounterMode = TIM_COUNTERMODE_UP;
  htim6.Init.Period = 53999;
  htim6.Init.AutoReloadPreload = TIM_AUTORELOAD_PRELOAD_ENABLE;
  if (HAL_TIM_Base_Init(&htim6) != HAL_OK)
  {
    Error_Handler();
  }
  sMasterConfig.MasterOutputTrigger = TIM_TRGO_UPDATE;
  sMasterConfig.MasterSlaveMode = TIM_MASTERSLAVEMODE_DISABLE;
  if (HAL_TIMEx_MasterConfigSynchronization(&htim6, &sMasterConfig) != HAL_OK)
  {
    Error_Handler();
  }

}

static void MX_TIM7_Init(void)
{

  TIM_MasterConfigTypeDef sMasterConfig = {0};

  htim7.Instance = TIM7;
  htim7.Init.Prescaler = 0;
  htim7.Init.CounterMode = TIM_COUNTERMODE_UP;
  htim7.Init.Period = 65535;
  htim7.Init.AutoReloadPreload = TIM_AUTORELOAD_PRELOAD_ENABLE;
  if (HAL_TIM_Base_Init(&htim7) != HAL_OK)
  {
    Error_Handler();
  }
  sMasterConfig.MasterOutputTrigger = TIM_TRGO_RESET;
  sMasterConfig.MasterSlaveMode = TIM_MASTERSLAVEMODE_DISABLE;
  if (HAL_TIMEx_MasterConfigSynchronization(&htim7, &sMasterConfig) != HAL_OK)
  {
    Error_Handler();
  }

}

static void MX_TIM8_Init(void)
{

  TIM_ClockConfigTypeDef sClockSourceConfig = {0};
  TIM_MasterConfigTypeDef sMasterConfig = {0};
  TIM_OC_InitTypeDef sConfigOC = {0};
  TIM_BreakDeadTimeConfigTypeDef sBreakDeadTimeConfig = {0};

  htim8.Instance = TIM8;
  htim8.Init.Prescaler = 0;
  htim8.Init.CounterMode = TIM_COUNTERMODE_UP;
  htim8.Init.Period = 10800;
  htim8.Init.ClockDivision = TIM_CLOCKDIVISION_DIV1;
  htim8.Init.RepetitionCounter = 0;
  htim8.Init.AutoReloadPreload = TIM_AUTORELOAD_PRELOAD_ENABLE;
  if (HAL_TIM_Base_Init(&htim8) != HAL_OK)
  {
    Error_Handler();
  }
  sClockSourceConfig.ClockSource = TIM_CLOCKSOURCE_INTERNAL;
  if (HAL_TIM_ConfigClockSource(&htim8, &sClockSourceConfig) != HAL_OK)
  {
    Error_Handler();
  }
  if (HAL_TIM_PWM_Init(&htim8) != HAL_OK)
  {
    Error_Handler();
  }
  sMasterConfig.MasterOutputTrigger = TIM_TRGO_UPDATE;
  sMasterConfig.MasterOutputTrigger2 = TIM_TRGO2_RESET;
  sMasterConfig.MasterSlaveMode = TIM_MASTERSLAVEMODE_DISABLE;
  if (HAL_TIMEx_MasterConfigSynchronization(&htim8, &sMasterConfig) != HAL_OK)
  {
    Error_Handler();
  }
  sConfigOC.OCMode = TIM_OCMODE_PWM1;
  sConfigOC.Pulse = 0;
  sConfigOC.OCPolarity = TIM_OCPOLARITY_HIGH;
  sConfigOC.OCFastMode = TIM_OCFAST_DISABLE;
  sConfigOC.OCIdleState = TIM_OCIDLESTATE_RESET;
  sConfigOC.OCNIdleState = TIM_OCNIDLESTATE_RESET;
  if (HAL_TIM_PWM_ConfigChannel(&htim8, &sConfigOC, TIM_CHANNEL_4) != HAL_OK)
  {
    Error_Handler();
  }
  sBreakDeadTimeConfig.OffStateRunMode = TIM_OSSR_DISABLE;
  sBreakDeadTimeConfig.OffStateIDLEMode = TIM_OSSI_DISABLE;
  sBreakDeadTimeConfig.LockLevel = TIM_LOCKLEVEL_OFF;
  sBreakDeadTimeConfig.DeadTime = 0;
  sBreakDeadTimeConfig.BreakState = TIM_BREAK_DISABLE;
  sBreakDeadTimeConfig.BreakPolarity = TIM_BREAKPOLARITY_HIGH;
  sBreakDeadTimeConfig.BreakFilter = 0;
  sBreakDeadTimeConfig.Break2State = TIM_BREAK2_DISABLE;
  sBreakDeadTimeConfig.Break2Polarity = TIM_BREAK2POLARITY_HIGH;
  sBreakDeadTimeConfig.Break2Filter = 0;
  sBreakDeadTimeConfig.AutomaticOutput = TIM_AUTOMATICOUTPUT_DISABLE;
  if (HAL_TIMEx_ConfigBreakDeadTime(&htim8, &sBreakDeadTimeConfig) != HAL_OK)
  {
    Error_Handler();
  }

}

static void MX_USART3_UART_Init(void)
{

  huart3.Instance = USART3;
  huart3.Init.BaudRate = 115200;
  huart3.Init.WordLength = UART_WORDLENGTH_8B;
  huart3.Init.StopBits = UART_STOPBITS_1;
  huart3.Init.Parity = UART_PARITY_NONE;
  huart3.Init.Mode = UART_MODE_TX_RX;
  huart3.Init.HwFlowCtl = UART_HWCONTROL_NONE;
  huart3.Init.OverSampling = UART_OVERSAMPLING_16;
  huart3.Init.OneBitSampling = UART_ONE_BIT_SAMPLE_DISABLE;
  huart3.AdvancedInit.AdvFeatureInit = UART_ADVFEATURE_NO_INIT;
  if (HAL_UART_Init(&huart3) != HAL_OK)
  {
    Error_Handler();
  }

}

static void MX_DMA_Init(void)
{

  /* DMA controller clock enable */
  __HAL_RCC_DMA1_CLK_ENABLE();
  __HAL_RCC_DMA2_CLK_ENABLE();

  /* DMA interrupt init */
  /* DMA1_Stream5_IRQn interrupt configuration */
  HAL_NVIC_SetPriority(DMA1_Stream5_IRQn, 0, 0);
  HAL_NVIC_EnableIRQ(DMA1_Stream5_IRQn);
  /* DMA1_Stream6_IRQn interrupt configuration */
  HAL_NVIC_SetPriority(DMA1_Stream6_IRQn, 0, 0);
  HAL_NVIC_EnableIRQ(DMA1_Stream6_IRQn);
  /* DMA2_Stream0_IRQn interrupt configuration */
  HAL_NVIC_SetPriority(DMA2_Stream0_IRQn, 1, 0);
  HAL_NVIC_EnableIRQ(DMA2_Stream0_IRQn);
  /* DMA2_Stream1_IRQn interrupt configuration */
  HAL_NVIC_SetPriority(DMA2_Stream1_IRQn, 1, 0);
  HAL_NVIC_EnableIRQ(DMA2_Stream1_IRQn);
  /* DMA2_Stream2_IRQn interrupt configuration */
  HAL_NVIC_SetPriority(DMA2_Stream2_IRQn, 2, 0);
  HAL_NVIC_EnableIRQ(DMA2_Stream2_IRQn);
  /* DMA2_Stream3_IRQn interrupt configuration */
  HAL_NVIC_SetPriority(DMA2_Stream3_IRQn, 1, 0);
  HAL_NVIC_EnableIRQ(DMA2_Stream3_IRQn);
  /* DMA2_Stream4_IRQn interrupt configuration */
  HAL_NVIC_SetPriority(DMA2_Stream4_IRQn, 1, 0);
  HAL_NVIC_EnableIRQ(DMA2_Stream4_IRQn);

}

static void MX_GPIO_Init(void)
{
  GPIO_InitTypeDef GPIO_InitStruct = {0};

  /* GPIO Ports Clock Enable */
  __HAL_RCC_GPIOE_CLK_ENABLE();
  __HAL_RCC_GPIOC_CLK_ENABLE();
  __HAL_RCC_GPIOF_CLK_ENABLE();
  __HAL_RCC_GPIOH_CLK_ENABLE();
  __HAL_RCC_GPIOA_CLK_ENABLE();
  __HAL_RCC_GPIOB_CLK_ENABLE();
  __HAL_RCC_GPIOG_CLK_ENABLE();
  __HAL_RCC_GPIOD_CLK_ENABLE();

  /*Configure GPIO pin Output Level */
  HAL_GPIO_WritePin(GPIOF, SD_CS_Pin|DISP_RST_Pin, GPIO_PIN_RESET);

  /*Configure GPIO pin Output Level */
  HAL_GPIO_WritePin(DISP_DC_GPIO_Port, DISP_DC_Pin, GPIO_PIN_RESET);

  /*Configure GPIO pin Output Level */
  HAL_GPIO_WritePin(GPIOB, Red_User_LED_Pin|Blue_User_LED_Pin, GPIO_PIN_RESET);

  /*Configure GPIO pin Output Level */
  HAL_GPIO_WritePin(DISP_CS_GPIO_Port, DISP_CS_Pin, GPIO_PIN_RESET);

  /*Configure GPIO pins : ENTER_USER_Pin BACK_Pin */
  GPIO_InitStruct.Pin = ENTER_USER_Pin|BACK_Pin;
  GPIO_InitStruct.Mode = GPIO_MODE_IT_RISING;
  GPIO_InitStruct.Pull = GPIO_NOPULL;
  HAL_GPIO_Init(GPIOC, &GPIO_InitStruct);

  /*Configure GPIO pins : SD_CS_Pin DISP_RST_Pin */
  GPIO_InitStruct.Pin = SD_CS_Pin|DISP_RST_Pin;
  GPIO_InitStruct.Mode = GPIO_MODE_OUTPUT_PP;
  GPIO_InitStruct.Pull = GPIO_NOPULL;
  GPIO_InitStruct.Speed = GPIO_SPEED_FREQ_LOW;
  HAL_GPIO_Init(GPIOF, &GPIO_InitStruct);

  /*Configure GPIO pin : DISP_DC_Pin */
  GPIO_InitStruct.Pin = DISP_DC_Pin;
  GPIO_InitStruct.Mode = GPIO_MODE_OUTPUT_PP;
  GPIO_InitStruct.Pull = GPIO_NOPULL;
  GPIO_InitStruct.Speed = GPIO_SPEED_FREQ_LOW;
  HAL_GPIO_Init(DISP_DC_GPIO_Port, &GPIO_InitStruct);

  /*Configure GPIO pin : PA2 */
  GPIO_InitStruct.Pin = GPIO_PIN_2;
  GPIO_InitStruct.Mode = GPIO_MODE_AF_PP;
  GPIO_InitStruct.Pull = GPIO_NOPULL;
  GPIO_InitStruct.Speed = GPIO_SPEED_FREQ_VERY_HIGH;
  GPIO_InitStruct.Alternate = GPIO_AF7_USART2;
  HAL_GPIO_Init(GPIOA, &GPIO_InitStruct);

  /*Configure GPIO pin : DISP_BUSY_Pin */
  GPIO_InitStruct.Pin = DISP_BUSY_Pin;
  GPIO_InitStruct.Mode = GPIO_MODE_INPUT;
  GPIO_InitStruct.Pull = GPIO_NOPULL;
  HAL_GPIO_Init(DISP_BUSY_GPIO_Port, &GPIO_InitStruct);

  /*Configure GPIO pin : SW_Pin */
  GPIO_InitStruct.Pin = SW_Pin;
  GPIO_InitStruct.Mode = GPIO_MODE_IT_FALLING;
  GPIO_InitStruct.Pull = GPIO_NOPULL;
  HAL_GPIO_Init(SW_GPIO_Port, &GPIO_InitStruct);

  /*Configure GPIO pin : ENTER_Pin */
  GPIO_InitStruct.Pin = ENTER_Pin;
  GPIO_InitStruct.Mode = GPIO_MODE_IT_RISING;
  GPIO_InitStruct.Pull = GPIO_NOPULL;
  HAL_GPIO_Init(ENTER_GPIO_Port, &GPIO_InitStruct);

  /*Configure GPIO pins : Red_User_LED_Pin Blue_User_LED_Pin */
  GPIO_InitStruct.Pin = Red_User_LED_Pin|Blue_User_LED_Pin;
  GPIO_InitStruct.Mode = GPIO_MODE_OUTPUT_PP;
  GPIO_InitStruct.Pull = GPIO_NOPULL;
  GPIO_InitStruct.Speed = GPIO_SPEED_FREQ_LOW;
  HAL_GPIO_Init(GPIOB, &GPIO_InitStruct);

  /*Configure GPIO pin : DISP_CS_Pin */
  GPIO_InitStruct.Pin = DISP_CS_Pin;
  GPIO_InitStruct.Mode = GPIO_MODE_OUTPUT_PP;
  GPIO_InitStruct.Pull = GPIO_NOPULL;
  GPIO_InitStruct.Speed = GPIO_SPEED_FREQ_LOW;
  HAL_GPIO_Init(DISP_CS_GPIO_Port, &GPIO_InitStruct);

  /*Configure GPIO pin : PD6 */
  GPIO_InitStruct.Pin = GPIO_PIN_6;
  GPIO_InitStruct.Mode = GPIO_MODE_AF_PP;
  GPIO_InitStruct.Pull = GPIO_NOPULL;
  GPIO_InitStruct.Speed = GPIO_SPEED_FREQ_VERY_HIGH;
  GPIO_InitStruct.Alternate = GPIO_AF7_USART2;
  HAL_GPIO_Init(GPIOD, &GPIO_InitStruct);

  /* EXTI interrupt init*/
  HAL_NVIC_SetPriority(EXTI9_5_IRQn, 0, 0);
  HAL_NVIC_EnableIRQ(EXTI9_5_IRQn);

  HAL_NVIC_SetPriority(EXTI15_10_IRQn, 1, 0);
  HAL_NVIC_EnableIRQ(EXTI15_10_IRQn);

}

/* USER CODE BEGIN 4 */

/**
 * @brief modifies the printf to output the strings to UART, so it can be receiced on a external terminal for debugging
 *
 */

/*printf() FUNCTIONS begin *********/
int __io_putchar(int ch)
{
	uint8_t c[1];
	c[0] = ch & 0x00FF;
	HAL_UART_Transmit(&huart3, &*c, 1, 10);
	return ch;
}

int _write(int file,char *ptr, int len)
{
	int DataIdx;
	for(DataIdx= 0; DataIdx< len; DataIdx++)
	{
		__io_putchar(*ptr++);
	}
	return len;
}
/*printf() FUNCTIONS end *********/

// GPIO-Button Debouncing

/** @brief button press interrupt function, for buttons placed near the Display
 */
void HAL_GPIO_EXTI_Callback(uint16_t GPIO_Pin) {

	Display.button_pressed_flag = true;	// set here to make sure that the display will be processed and updated when for example a note or octave is changed

	if((GPIO_Pin == BACK_Pin) && (Display.BACK_Debounce_State == true)) {

		// keyboard goes down by one octave if not in drumcomputer settings, sequencer settings and adsr reset
		if(! ((Display.pagePosition==3 && Display.currentDrumcomputer>0) || (Display.pagePosition==4 && Display.currentSequencer>0) || (Display.pagePosition == 5 && Display.currentADSR == 7)) ) {
			if(Display.Keyboard_Octave > 0)
				Display.Keyboard_Octave--;
		}

		// ACHTUNG ACHTUNG, SEITENZAHL USW. BEACHTEN!!!
		// Tremolo Rate Index setting to change the rate by button pressing
		if(Display.pagePosition == 9 && Display.JoystickParameterPosition == 2) {
			if(Display.Tremolo_Rate_Index > 0)
				Display.Tremolo_Rate_Index--;
		}

		// ACHTUNG ACHTUNG, SEITENZAHL USW. BEACHTEN!!!
		// Auto-WahWah LFO Frequency Index setting to change the rate by button pressing
		if(Display.pagePosition == 8 && Display.currentWahWah > 0 && Display.JoystickParameterPosition == 4) {
			if(Display.WahWah_LFOfreq_Index > 0)
				Display.WahWah_LFOfreq_Index--;
		}

		// ACHTUNG ACHTUNG, SEITENZAHL USW. BEACHTEN!!!
		// Sequencer notes and octaves changed by putton pressing
		if(Display.pagePosition == 3 && Display.currentDrumcomputer == 0) {
			if(Display.JoystickParameterPosition == 3) {	// Sequencer Note 1 down
				if(Display.Sequencer_Noteindex[0] > 0)
					Display.Sequencer_Noteindex[0]--;
			}
			else if(Display.JoystickParameterPosition == 4) {	// Sequencer Octave 1 down
				if(Display.Sequencer_Octave[0] > 0)
					Display.Sequencer_Octave[0]--;
			}
			else if(Display.JoystickParameterPosition == 5) {	// Sequencer Note 2 down
				if(Display.Sequencer_Noteindex[1] > 0)
					Display.Sequencer_Noteindex[1]--;
			}
			else if(Display.JoystickParameterPosition == 6) {	// Sequencer Octave 2 down
				if(Display.Sequencer_Octave[1] > 0)
					Display.Sequencer_Octave[1]--;
			}
			else if(Display.JoystickParameterPosition == 7) {	// Sequencer Note 3 down
				if(Display.Sequencer_Noteindex[2] > 0)
					Display.Sequencer_Noteindex[2]--;
			}
			else if(Display.JoystickParameterPosition == 8) {	// Sequencer Octave 3 down
				if(Display.Sequencer_Octave[2] > 0)
					Display.Sequencer_Octave[2]--;
			}
		}

		// ACHTUNG ACHTUNG, SEITENZAHL USW. BEACHTEN!!!
		// Voices notes and octaves changed by putton pressing
		if(Display.pagePosition == 5 && Display.currentVoice > 0) {

			// Voices Notes
			if(Display.JoystickParameterPosition == 1) {	// Voices [1,2,3] Note up

				// Noteindex decreased the same way for all Scale Modes (Freestyle, Major and Minor)
				if(Display.Voices_Noteindex[Display.currentVoice-1] > 0)
					Display.Voices_Noteindex[Display.currentVoice-1]--;
			}

			// Octaves
			else if(Display.JoystickParameterPosition == 2) {	// Voices [1,2,3] Octave down
				if(Display.Voices_Octave[Display.currentVoice-1] > 0)
					Display.Voices_Octave[Display.currentVoice-1]--;
			}
		}

		// ACHTUNG ACHTUNG, SEITENZAHL USW. BEACHTEN!!!
		// KeyNote and mode changed by putton pressing
		if(Display.pagePosition == 11) {

			if(Display.JoystickParameterPosition == 1) {	// KeyNote (e.g. C)

				if(Display.KeyNoteIndex > 0) {				// 12 keys per octave

					Display.KeyNoteIndex--;
				}
			}
			else if(Display.JoystickParameterPosition == 2) {	// Mode (Freestyle, Major, Minor)

				if(Display.ScaleMode > 0){

					// Update Scale Mode
					Display.ScaleMode--;
				}
			}

			// Turn off voices
			Display.Voices_ONOFF[VOICES_ID]   = false;
			Display.Voices_ONOFF[VOICES_ID+1] = false;
			Display.Voices_ONOFF[VOICES_ID+2] = false;

			strcpy(Display.value_str_voices_overview[0], "OFF");
			strcpy(Display.value_str_voices_overview[1], "OFF");
			strcpy(Display.value_str_voices_overview[2], "OFF");

			// Reset Voices to root note when Mode changed
			Display.Voices_Noteindex[VOICES_ID]   = Display.last_Voices_Noteindex[VOICES_ID]   = 0;
			Display.Voices_Noteindex[VOICES_ID+1] = Display.last_Voices_Noteindex[VOICES_ID+1] = 0;
			Display.Voices_Noteindex[VOICES_ID+2] = Display.last_Voices_Noteindex[VOICES_ID+2] = 0;

			Display.Voices_Note[VOICES_ID]   = (uint8_t)(keys[(uint8_t)Display.Voices_Noteindex[VOICES_ID  ] + Display.KeyNoteIndex]);
			Display.Voices_Note[VOICES_ID+1] = (uint8_t)(keys[(uint8_t)Display.Voices_Noteindex[VOICES_ID+1] + Display.KeyNoteIndex]);
			Display.Voices_Note[VOICES_ID+2] = (uint8_t)(keys[(uint8_t)Display.Voices_Noteindex[VOICES_ID+2] + Display.KeyNoteIndex]);

			// Turn off sequencer
			Display.Sequencer_ONOFF = false;

			// Reset Sequencer to root note when Mode changed
			Display.Sequencer_Noteindex[0] = Display.last_Sequencer_Noteindex[0] = 0;
			Display.Sequencer_Noteindex[1] = Display.last_Sequencer_Noteindex[1] = 0;
			Display.Sequencer_Noteindex[2] = Display.last_Sequencer_Noteindex[2] = 0;

			Display.Sequencer_Note[0] = (uint8_t)(keys[(uint8_t)Display.Sequencer_Noteindex[0] + Display.KeyNoteIndex]);
			Display.Sequencer_Note[1] = (uint8_t)(keys[(uint8_t)Display.Sequencer_Noteindex[1] + Display.KeyNoteIndex]);
			Display.Sequencer_Note[2] = (uint8_t)(keys[(uint8_t)Display.Sequencer_Noteindex[2] + Display.KeyNoteIndex]);

			freq_index_SN1 = Get_Note_Index(Display.Sequencer_Note[0], Display.Sequencer_Octave[0]);
			freq_index_SN2 = Get_Note_Index(Display.Sequencer_Note[1], Display.Sequencer_Octave[1]);
			freq_index_SN3 = Get_Note_Index(Display.Sequencer_Note[2], Display.Sequencer_Octave[2]);

			// FOR: all steps in sequencer
			for(int i=0; i<FourFour; i++) {

				// INIT: Sequencer start index
				current_LUT_index_SN1[i] = LUT_STARTINDEX[freq_index_SN1];
				current_LUT_index_SN2[i] = LUT_STARTINDEX[freq_index_SN2];
				current_LUT_index_SN3[i] = LUT_STARTINDEX[freq_index_SN3];
			}

			strcpy(Display.value_str_sequencer[0], "OFF");
			sprintf(Display.value_str_sequencer[1], "%c", Display.Sequencer_Note[0]);
			sprintf(Display.value_str_sequencer[3], "%c", Display.Sequencer_Note[1]);
			sprintf(Display.value_str_sequencer[5], "%c", Display.Sequencer_Note[2]);
		}

		// ACHTUNG ACHTUNG, SEITENZAHL USW. BEACHTEN!!!
		// Sources down
		if(Display.pagePosition == 2) {	// Drumfilter Cutoff Source
			if(Display.currentDrumcomputer == 6 && Display.Drumfilter_Cutoff_Source > 0)
				Display.Drumfilter_Cutoff_Source--;
		}
		else if(Display.pagePosition == 5) {
			if(Display.currentVoice > 0) {	// Voices Sources
				if(Display.JoystickParameterPosition == 3 && Display.Voice_Note_Sources[Display.currentVoice-1] > 0)
					Display.Voice_Note_Sources[Display.currentVoice-1]--;
				if(Display.JoystickParameterPosition == 4 && Display.Voice_Octave_Sources[Display.currentVoice-1] > 0)
					Display.Voice_Octave_Sources[Display.currentVoice-1]--;
			}
		}
		else if(Display.pagePosition == 6) {
			if(Display.currentADSR > 0) {	// ADSR Sources
				if(Display.JoystickParameterPosition == 1 && Display.ADSR_Sources[0] > 0)
					Display.ADSR_Sources[0]--;
				else if(Display.JoystickParameterPosition == 2 && Display.ADSR_Sources[1] > 0)
					Display.ADSR_Sources[1]--;
				else if(Display.JoystickParameterPosition == 3 && Display.ADSR_Sources[2] > 0)
					Display.ADSR_Sources[2]--;
				else if(Display.JoystickParameterPosition == 4 && Display.ADSR_Sources[3] > 0)
					Display.ADSR_Sources[3]--;
				else if(Display.JoystickParameterPosition == 5 && Display.ADSR_Sources[4] > 0)
					Display.ADSR_Sources[4]--;
			}
		}
		else if(Display.pagePosition == 7) {
			if(Display.currentBand > 0) {	// EQ Sources
				if(Display.JoystickParameterPosition == 4 && Display.EQ_Q_factor_Sources[Display.currentBand-1] > 0)
					Display.EQ_Q_factor_Sources[Display.currentBand-1]--;
				else if(Display.JoystickParameterPosition == 5 && Display.EQ_Cutoff_Sources[Display.currentBand-1] > 0)
					Display.EQ_Cutoff_Sources[Display.currentBand-1]--;
				else if(Display.JoystickParameterPosition == 6 && Display.EQ_Gain_Sources[Display.currentBand-1] > 0)
					Display.EQ_Gain_Sources[Display.currentBand-1]--;
			}
		}
		else if(Display.pagePosition == 8) {
			if(Display.currentWahWah == 0) {	// Distortion Sources
				if(Display.JoystickParameterPosition == 4 && Display.Distortion_Sources > 0) {
					Display.Distortion_Sources--;
				}
			}
			else if(Display.currentWahWah > 0) {	// WahWah Sources
				if(Display.JoystickParameterPosition == 3 && Display.WahWah_Sources[0] > 0)
					Display.WahWah_Sources[0]--;
				else if(Display.JoystickParameterPosition == 4 && Display.WahWah_Sources[1] > 0)
					Display.WahWah_Sources[1]--;
				else if(Display.JoystickParameterPosition == 5 && Display.WahWah_Sources[2] > 0)
					Display.WahWah_Sources[2]--;
				else if(Display.JoystickParameterPosition == 6 && Display.WahWah_Sources[3] > 0)
					Display.WahWah_Sources[3]--;
				else if(Display.JoystickParameterPosition == 7 && Display.WahWah_Sources[4] > 0)
					Display.WahWah_Sources[4]--;
				else if(Display.JoystickParameterPosition == 8 && Display.WahWah_Sources[5] > 0)
					Display.WahWah_Sources[5]--;
			}
		}
		else if(Display.pagePosition == 9) {	// Tremolo Sources
			if(Display.JoystickParameterPosition == 4 && Display.Tremolo_Sources[0] > 0)
				Display.Tremolo_Sources[0]--;
			else if(Display.JoystickParameterPosition == 5 && Display.Tremolo_Sources[1] > 0)
				Display.Tremolo_Sources[1]--;
		}

		HAL_TIM_Base_Start_IT(&htim2);
		Display.BACK_Debounce_State = false;
	}

	else if((GPIO_Pin == ENTER_Pin) && (Display.ENTER_Debounce_State == true)) {

		// ACHTUNG ACHTUNG, SEITENZAHL USW. BEACHTEN!!!
		// keyboard goes up by one octave if not in drumcomputer settings, sequencer settings and adsr reset
		if(! ((Display.pagePosition==3 && Display.currentDrumcomputer>0) || (Display.pagePosition==4 && Display.currentSequencer>0) || (Display.pagePosition == 5 && Display.currentADSR == 7)) ) {
			if(Display.Keyboard_Octave < LUT_OCTAVES-1)
				Display.Keyboard_Octave++;
		}

		// set drumcomputer steps
		if(Display.EditDrums == true) {
			// invert/toggle state of the drum matrix entry, where the cursor points at at the moment
			Display.DrumMatrix[Display.CurrentSampleRow-1][Display.CurrentDrumstep-1] = !Display.DrumMatrix[Display.CurrentSampleRow-1][Display.CurrentDrumstep-1];

			if(Display.DrumMatrix[Display.CurrentSampleRow-1][Display.CurrentDrumstep-1] == true) {
				DISPLAY_SetDrumcomputerStep();
				Display.UpdateDisplay = true;
			}
			else if(Display.DrumMatrix[Display.CurrentSampleRow-1][Display.CurrentDrumstep-1] == false) {
				DISPLAY_DeleteDrumcomputerStep();
				Display.UpdateDisplay = true;
			}
		}

		// set sequencer steps
		if(Display.EditSteps == true) {
			// invert/toggle state of the sequencer matrix entry, where the cursor points at at the moment
			Display.SequencerMatrix[Display.CurrentNoteRow-1][Display.CurrentSequencestep-1] = !Display.SequencerMatrix[Display.CurrentNoteRow-1][Display.CurrentSequencestep-1];

			if(Display.SequencerMatrix[Display.CurrentNoteRow-1][Display.CurrentSequencestep-1] == true) {
				DISPLAY_SetSequencerStep();
				Display.UpdateDisplay = true;
			}
			else if(Display.SequencerMatrix[Display.CurrentNoteRow-1][Display.CurrentSequencestep-1] == false) {
				DISPLAY_DeleteSequencerStep();
				Display.UpdateDisplay = true;
			}
		}

		// ACHTUNG ACHTUNG, SEITENZAHL USW. BEACHTEN!!!
		// Load single sample / load Drumkit from SD card
		if((Display.pagePosition==10) ||(Display.pagePosition==3 && Display.currentDrumcomputer>0 && Display.JoystickParameterPosition==3))
			Display.LoadDrumkit = true;

		// ACHTUNG ACHTUNG, SEITENZAHL USW. BEACHTEN!!!
		// Tremolo Rate Index setting to change the rate by button pressing
		if(Display.pagePosition == 9 && Display.JoystickParameterPosition == 2) {
			if(Display.Tremolo_Rate_Index < 7)
				Display.Tremolo_Rate_Index++;
		}

		// ACHTUNG ACHTUNG, SEITENZAHL USW. BEACHTEN!!!
		// Auto-WahWah LFO Frequency Index setting to change the rate by button pressing
		if(Display.pagePosition == 8 && Display.currentWahWah > 0 && Display.JoystickParameterPosition == 4) {
			if(Display.WahWah_LFOfreq_Index < 7)
				Display.WahWah_LFOfreq_Index++;
		}

		// ACHTUNG ACHTUNG, SEITENZAHL USW. BEACHTEN!!!
		// Sequencer notes and octaves changed by putton pressing
		if(Display.pagePosition == 3 && Display.currentDrumcomputer == 0) {

			if(Display.JoystickParameterPosition == 3) {	// Sequencer Note 1 up

				if(Display.ScaleMode == FREESTYLE){
					if(Display.Sequencer_Noteindex[0] < 12)	// 12 keys per octave + deep C
						Display.Sequencer_Noteindex[0]++;
				}
				else if(Display.ScaleMode == MAJOR){
					if(Display.Sequencer_Noteindex[0] < 7)	// 7 keys per octave + deep root
						Display.Sequencer_Noteindex[0]++;
				}
				else if(Display.ScaleMode == MINOR){
					if(Display.Sequencer_Noteindex[0] < 7)	// 7 keys per octave + deep root
						Display.Sequencer_Noteindex[0]++;
				}
			}
			else if(Display.JoystickParameterPosition == 4) {	// Sequencer Octave 1 up

				if(Display.Sequencer_Octave[0] < 5)	// maximum 6 octaves
					Display.Sequencer_Octave[0]++;
			}
			else if(Display.JoystickParameterPosition == 5) {	// Sequencer Note 2 up

				if(Display.ScaleMode == FREESTYLE){
					if(Display.Sequencer_Noteindex[1] < 12)	// 12 keys per octave + deep C
						Display.Sequencer_Noteindex[1]++;
				}
				else if(Display.ScaleMode == MAJOR){
					if(Display.Sequencer_Noteindex[1] < 7)	// 7 keys per octave + deep root
						Display.Sequencer_Noteindex[1]++;
				}
				else if(Display.ScaleMode == MINOR){
					if(Display.Sequencer_Noteindex[1] < 7)	// 7 keys per octave + deep root
						Display.Sequencer_Noteindex[1]++;
				}
			}
			else if(Display.JoystickParameterPosition == 6) {	// Sequencer Octave 2 up

				if(Display.Sequencer_Octave[1] < 5)	// maximum 6 octaves
					Display.Sequencer_Octave[1]++;
			}
			else if(Display.JoystickParameterPosition == 7) {	// Sequencer Note 3 up

				if(Display.ScaleMode == FREESTYLE){
					if(Display.Sequencer_Noteindex[2] < 12)	// 12 keys per octave + deep C
						Display.Sequencer_Noteindex[2]++;
				}
				else if(Display.ScaleMode == MAJOR){
					if(Display.Sequencer_Noteindex[2] < 7)	// 7 keys per octave + deep root
						Display.Sequencer_Noteindex[2]++;
				}
				else if(Display.ScaleMode == MINOR){
					if(Display.Sequencer_Noteindex[2] < 7)	// 7 keys per octave + deep root
						Display.Sequencer_Noteindex[2]++;
				}
			}
			else if(Display.JoystickParameterPosition == 8) {	// Sequencer Octave 3 up

				if(Display.Sequencer_Octave[2] < 5)	// maximum 6 octaves
					Display.Sequencer_Octave[2]++;
			}
		}

		// ACHTUNG ACHTUNG, SEITENZAHL USW. BEACHTEN!!!
		// Voices notes and octaves changed by putton pressing
		if(Display.pagePosition == 5 && Display.currentVoice > 0) {

			// Voices Notes
			if(Display.JoystickParameterPosition == 1) {	// Voices [1,2,3] Note up

				if(Display.ScaleMode == FREESTYLE){
					if(Display.Voices_Noteindex[Display.currentVoice-1] < 12)	// 12 keys per octave + deep C
						Display.Voices_Noteindex[Display.currentVoice-1]++;
				}
				else if(Display.ScaleMode == MAJOR){
					if(Display.Voices_Noteindex[Display.currentVoice-1] < 7)	// 7 keys per octave + deep root
						Display.Voices_Noteindex[Display.currentVoice-1]++;
				}
				else if(Display.ScaleMode == MINOR){
					if(Display.Voices_Noteindex[Display.currentVoice-1] < 7)	// 7 keys per octave + deep root
						Display.Voices_Noteindex[Display.currentVoice-1]++;
				}
			}

			// Octaves
			else if(Display.JoystickParameterPosition == 2) {	// Voices [1,2,3] Octave up
				if(Display.Voices_Octave[Display.currentVoice-1] < 5)	// maximum 6 octaves
					Display.Voices_Octave[Display.currentVoice-1]++;
			}
		}

		// ACHTUNG ACHTUNG, SEITENZAHL USW. BEACHTEN!!!
		// KeyNote and mode changed by putton pressing
		if(Display.pagePosition == 11) {

			if(Display.JoystickParameterPosition == 1) {	// KeyNote (e.g. C)

				if(Display.KeyNoteIndex < 12) {				// 12 keys per octave

					Display.KeyNoteIndex++;
				}
			}
			else if(Display.JoystickParameterPosition == 2) {	// Mode (Freestyle, Major, Minor)

				if(Display.ScaleMode < 2) {

					// Update Scale Mode
					Display.ScaleMode++;
				}
			}

			// Turn off voices
			Display.Voices_ONOFF[VOICES_ID]   = false;
			Display.Voices_ONOFF[VOICES_ID+1] = false;
			Display.Voices_ONOFF[VOICES_ID+2] = false;

			strcpy(Display.value_str_voices_overview[0], "OFF");
			strcpy(Display.value_str_voices_overview[1], "OFF");
			strcpy(Display.value_str_voices_overview[2], "OFF");

			// Reset Voices to root note when Mode changed
			Display.Voices_Noteindex[VOICES_ID]   = Display.last_Voices_Noteindex[VOICES_ID]   = 0;
			Display.Voices_Noteindex[VOICES_ID+1] = Display.last_Voices_Noteindex[VOICES_ID+1] = 0;
			Display.Voices_Noteindex[VOICES_ID+2] = Display.last_Voices_Noteindex[VOICES_ID+2] = 0;

			Display.Voices_Note[VOICES_ID]   = (uint8_t)(keys[(uint8_t)Display.Voices_Noteindex[VOICES_ID  ] + Display.KeyNoteIndex]);
			Display.Voices_Note[VOICES_ID+1] = (uint8_t)(keys[(uint8_t)Display.Voices_Noteindex[VOICES_ID+1] + Display.KeyNoteIndex]);
			Display.Voices_Note[VOICES_ID+2] = (uint8_t)(keys[(uint8_t)Display.Voices_Noteindex[VOICES_ID+2] + Display.KeyNoteIndex]);

			// Turn off sequencer
			Display.Sequencer_ONOFF = false;

			// Reset Sequencer to root note when Mode changed
			Display.Sequencer_Noteindex[0] = Display.last_Sequencer_Noteindex[0] = 0;
			Display.Sequencer_Noteindex[1] = Display.last_Sequencer_Noteindex[1] = 0;
			Display.Sequencer_Noteindex[2] = Display.last_Sequencer_Noteindex[2] = 0;

			Display.Sequencer_Note[0] = (uint8_t)(keys[(uint8_t)Display.Sequencer_Noteindex[0] + Display.KeyNoteIndex]);
			Display.Sequencer_Note[1] = (uint8_t)(keys[(uint8_t)Display.Sequencer_Noteindex[1] + Display.KeyNoteIndex]);
			Display.Sequencer_Note[2] = (uint8_t)(keys[(uint8_t)Display.Sequencer_Noteindex[2] + Display.KeyNoteIndex]);

			freq_index_SN1 = Get_Note_Index(Display.Sequencer_Note[0], Display.Sequencer_Octave[0]);
			freq_index_SN2 = Get_Note_Index(Display.Sequencer_Note[1], Display.Sequencer_Octave[1]);
			freq_index_SN3 = Get_Note_Index(Display.Sequencer_Note[2], Display.Sequencer_Octave[2]);

			// FOR: all steps in sequencer
			for(int i=0; i<FourFour; i++) {

				// INIT: Sequencer start index
				current_LUT_index_SN1[i] = LUT_STARTINDEX[freq_index_SN1];
				current_LUT_index_SN2[i] = LUT_STARTINDEX[freq_index_SN2];
				current_LUT_index_SN3[i] = LUT_STARTINDEX[freq_index_SN3];
			}

			strcpy(Display.value_str_sequencer[0], "OFF");
			sprintf(Display.value_str_sequencer[1], "%c", Display.Sequencer_Note[0]);
			sprintf(Display.value_str_sequencer[3], "%c", Display.Sequencer_Note[1]);
			sprintf(Display.value_str_sequencer[5], "%c", Display.Sequencer_Note[2]);
		}

		// ACHTUNG ACHTUNG, SEITENZAHL USW. BEACHTEN!!!
		// Set preset by putton pressing
		if(Display.pagePosition == -1)
			Display.SetPreset = true;

		// ACHTUNG ACHTUNG, SEITENZAHL USW. BEACHTEN!!!
		// Reset of different modules by putton pressing
		if(Display.pagePosition == 2 && Display.currentDrumcomputer == 8)				// Drumcomputer Reset
			Display.Reset = true;
		else if(Display.pagePosition == 3 && Display.currentSequencer == 8)				// Sequencer Reset
			Display.Reset = true;
		else if(Display.pagePosition == 4 && Display.currentVoice == 5)					// Voices Reset
			Display.Reset = true;
		else if(Display.pagePosition == 5 && Display.currentADSR == 7)					// ADSR Reset
			Display.Reset = true;
		else if(Display.pagePosition == 6 && Display.currentBand == 6)					// EQ Reset
			Display.Reset = true;
		else if(Display.pagePosition == 7 && Display.currentWahWah == 3)				// WahWah Reset
			Display.Reset = true;
		else if(Display.pagePosition == 8 && Display.JoystickParameterPosition == 5)	// Distortion Reset
			Display.Reset = true;
		else if(Display.pagePosition == 9 && Display.JoystickParameterPosition == 6)	// Tremolo Reset
			Display.Reset = true;

		// ACHTUNG ACHTUNG, SEITENZAHL USW. BEACHTEN!!!
		// Sources up
		if(Display.pagePosition == 2) {	// Drumfilter Cutoff Source
			if(Display.currentDrumcomputer == 6 && Display.Drumfilter_Cutoff_Source < (NUMBER_OF_SOURCES-1))
				Display.Drumfilter_Cutoff_Source++;
		}
		else if(Display.pagePosition == 5) {
			if(Display.currentVoice > 0) {	// Voices Sources
				if(Display.JoystickParameterPosition == 3 && Display.Voice_Note_Sources[Display.currentVoice-1] < (NUMBER_OF_SOURCES-1))
					Display.Voice_Note_Sources[Display.currentVoice-1]++;
				if(Display.JoystickParameterPosition == 4 && Display.Voice_Octave_Sources[Display.currentVoice-1] < (NUMBER_OF_SOURCES-1))
					Display.Voice_Octave_Sources[Display.currentVoice-1]++;
			}
		}
		else if(Display.pagePosition == 6) {
			if(Display.currentADSR > 0) {	// ADSR Sources
				if(Display.JoystickParameterPosition == 1 && Display.ADSR_Sources[0] < (NUMBER_OF_SOURCES-1))
					Display.ADSR_Sources[0]++;
				else if(Display.JoystickParameterPosition == 2 && Display.ADSR_Sources[1] < (NUMBER_OF_SOURCES-1))
					Display.ADSR_Sources[1]++;
				else if(Display.JoystickParameterPosition == 3 && Display.ADSR_Sources[2] < (NUMBER_OF_SOURCES-1))
					Display.ADSR_Sources[2]++;
				else if(Display.JoystickParameterPosition == 4 && Display.ADSR_Sources[3] < (NUMBER_OF_SOURCES-1))
					Display.ADSR_Sources[3]++;
				else if(Display.JoystickParameterPosition == 5 && Display.ADSR_Sources[4] < (NUMBER_OF_SOURCES-1))
					Display.ADSR_Sources[4]++;
			}
		}
		else if(Display.pagePosition == 7) {
			if(Display.currentBand > 0) {	// EQ Sources
				if(Display.JoystickParameterPosition == 4 && Display.EQ_Q_factor_Sources[Display.currentBand-1] < (NUMBER_OF_SOURCES-1))
					Display.EQ_Q_factor_Sources[Display.currentBand-1]++;
				else if(Display.JoystickParameterPosition == 5 && Display.EQ_Cutoff_Sources[Display.currentBand-1] < (NUMBER_OF_SOURCES-1))
					Display.EQ_Cutoff_Sources[Display.currentBand-1]++;
				else if(Display.JoystickParameterPosition == 6 && Display.EQ_Gain_Sources[Display.currentBand-1] < (NUMBER_OF_SOURCES-1))
					Display.EQ_Gain_Sources[Display.currentBand-1]++;
			}
		}
		else if(Display.pagePosition == 8) {
			if(Display.currentWahWah == 0) {	// Distortion Sources
				if(Display.JoystickParameterPosition == 4 && Display.Distortion_Sources < (NUMBER_OF_SOURCES-1)) {
					Display.Distortion_Sources++;
				}
			}
			else if(Display.currentWahWah > 0) {	// WahWah Sources
				if(Display.JoystickParameterPosition == 3 && Display.WahWah_Sources[0] < (NUMBER_OF_SOURCES-1))
					Display.WahWah_Sources[0]++;
				else if(Display.JoystickParameterPosition == 4 && Display.WahWah_Sources[1] < (NUMBER_OF_SOURCES-1))
					Display.WahWah_Sources[1]++;
				else if(Display.JoystickParameterPosition == 5 && Display.WahWah_Sources[2] < (NUMBER_OF_SOURCES-1))
					Display.WahWah_Sources[2]++;
				else if(Display.JoystickParameterPosition == 6 && Display.WahWah_Sources[3] < (NUMBER_OF_SOURCES-1))
					Display.WahWah_Sources[3]++;
				else if(Display.JoystickParameterPosition == 7 && Display.WahWah_Sources[4] < (NUMBER_OF_SOURCES-1))
					Display.WahWah_Sources[4]++;
				else if(Display.JoystickParameterPosition == 8 && Display.WahWah_Sources[5] < (NUMBER_OF_SOURCES-1))
					Display.WahWah_Sources[5]++;
			}
		}
		else if(Display.pagePosition == 9) {	// Tremolo Sources
			if(Display.JoystickParameterPosition == 4 && Display.Tremolo_Sources[0] < (NUMBER_OF_SOURCES-1))
				Display.Tremolo_Sources[0]++;
			else if(Display.JoystickParameterPosition == 5 && Display.Tremolo_Sources[1] < (NUMBER_OF_SOURCES-1))
				Display.Tremolo_Sources[1]++;
		}

		HAL_TIM_Base_Start_IT(&htim4);
		Display.ENTER_Debounce_State = false;
	}
	else {
		__NOP();
	}
}
/**
 * @brief Callback for every timer interruppt
 *
 * @param htim
 */
void HAL_TIM_PeriodElapsedCallback(TIM_HandleTypeDef *htim) {
	// Prevent unused argument(s) compilation warning
	UNUSED(htim);

	if(htim->Instance == TIM2) {
		//if(HAL_GPIO_ReadPin(BACK_GPIO_Port, BACK_Pin) == GPIO_PIN_SET) {
		if(HAL_GPIO_ReadPin(BACK_GPIO_Port, BACK_Pin) == GPIO_PIN_RESET) {	// check regarding pullup/pulldown
			Display.BACK = true;
			Display.BACK_Debounce_State = true;
			HAL_TIM_Base_Stop_IT(&htim2);
		}
	}
	else if(htim->Instance == TIM4) {
		if(HAL_GPIO_ReadPin(ENTER_GPIO_Port, ENTER_Pin) == GPIO_PIN_RESET) {	// check regarding pullup/pulldown
			Display.ENTER = true;
			Display.ENTER_Debounce_State = true;
			HAL_TIM_Base_Stop_IT(&htim4);
		}
	}
	else {
		__NOP();
	}
}
/* USER CODE END 4 */

void Error_Handler(void)
{
}

/************************ (C) COPYRIGHT STMicroelectronics *****END OF FILE****/
